# HR_C7000_DM32 register map
Vendor: Dahua Technology (chip); Baofeng (radio product); Series: HR_C7000; File version: 0.1-dm32re-draft
CPU: other r0p0, little endian, no MPU, no FPU, 0 interrupt priority bits
Registers are 32-bit, read-write, reset 0x0 unless marked. A register's access mark holds for its fields unless they carry their own. Offsets are from the block's base; [hi:lo] are bit positions.

## I2C0 — I2C0, Synopsys DesignWare APB I2C master/slave (DS §5.1, p.218-243). FW: no direct access or base literal found in program flash. QEMU docs record the ALPU-MP anti-clone handshake (I2C address 0x7a) on this controller; the IRAM code also contains a bit-banged GPIO I2C routine addressing 0x7a. Which path the stock firmware uses is not settled here.
Base 0x14060000
Same registers: I2C1 0x14070000, I2C2 0x14080000
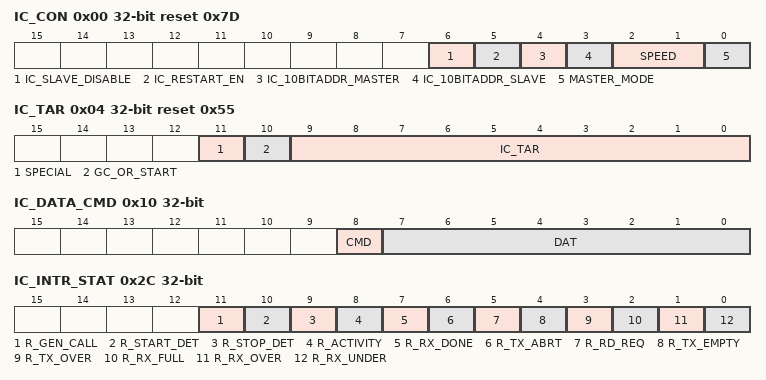
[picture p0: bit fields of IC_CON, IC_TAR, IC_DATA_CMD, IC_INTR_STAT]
0x00 IC_CON reset 0x7D — I2C Control registers. DS §5.1.6.1 p.226. Reset 0x7d (DS).
  [6] IC_SLAVE_DISABLE — I2C functions as a slave after reset. 0: slave enabled; 1: slave disabled [reset 0x1] [access RW]
  [5] IC_RESTART_EN — As master, whether RESTART is supported. 0: off; 1: enabled [reset 0x1] [access RW]
  [4] IC_10BITADDR_MASTER — As master, address mode. 0: 7-bit; 1: 10-bit [reset 0x1] [access RW]
  [3] IC_10BITADDR_SLAVE — As slave, address mode the I2C responds to. 0: 7-bit; 1: 10-bit [reset 0x1] [access RW]
  [2:1] SPEED — Speed mode. 1: standard (100 kbit/s); 2: fast (400 kbit/s); 3: high speed (3.4 Mbit/s, not supported) [reset 0x2] [access RW]
  [0] MASTER_MODE — Master enable. 0: master off; 1: master enabled [reset 0x1] [access RW]
0x04 IC_TAR reset 0x55 — I2C Destination Address Register. DS §5.1.6.2 p.228. Reset 0x55 (DS).
  [11] SPECIAL — Indicates whether the software executes a general call or start byte command. ( Not supported These two functions ) [reset 0x0] [access RW]
  [10] GC_OR_START — only when bit 11 is set to 1. It indicates whether the software is executing a general call or a start byte command. 0 : Broadcast call 1 : Start byte [reset 0x0] [access RW]
  [9:0] IC_TAR — Indicates the target slave address when I2C is used as the master . [reset 0x55] [access RW]
0x10 IC_DATA_CMD — I2C Send and receive data buffers and. DS §5.1.6.3 p.228. Reset 0x0 (DS).
  [8] CMD wo — I2C is used as a master , read and write control bits. 1 : Read 0 : Write [reset 0x0] [access WO]
  [7:0] DAT — Data sent to or received from the I2C bus . [reset 0x0] [access RW]
0x1C IC_FS_SCL_HCNT reset 0x5A — Fast SCL High level count. DS §5.1.6.4 p.228. Reset 0x5a (DS).
  [15:0] IC_FS_SCL_HCNT — Set in fast mode, SCL clock is active high when ic_clk Number of cycles [reset 0x5a] [access RW]
0x20 IC_FS_SCL_LCNT reset 0xA0 — Fast SCL Low level count. DS §5.1.6.5 p.228. Reset 0xa0 (DS).
  [15:0] IC_FS_SCL_LCNT — Set in fast mode, SCL clock is active low when ic_clk Number of cycles [reset 0xa0] [access RW]
0x2C IC_INTR_STAT ro — Interrupt Status. DS §5.1.6.6 p.230. Reset 0x0 (DS).
  [11] R_GEN_CALL — IC_RAW_INTR_STAT register for detailed explanation [reset 0x0] [access RO]
  [10] R_START_DET — R_START_DET [reset 0x0] [access RO]
  [9] R_STOP_DET — R_STOP_DET [reset 0x0] [access RO]
  [8] R_ACTIVITY — R_ACTIVITY [reset 0x0] [access RO]
  [7] R_RX_DONE — R_RX_DONE [reset 0x0] [access RO]
  [6] R_TX_ABRT — R_TX_ABRT [reset 0x0] [access RO]
  [5] R_RD_REQ — R_RD_REQ [reset 0x0] [access RO]
  [4] R_TX_EMPTY — R_TX_EMPTY [reset 0x0] [access RO]
  [3] R_TX_OVER — R_TX_OVER [reset 0x0] [access RO]
  [2] R_RX_FULL — R_RX_FULL [reset 0x0] [access RO]
  [1] R_RX_OVER — R_RX_OVER [reset 0x0] [access RO]
  [0] R_RX_UNDER — R_RX_UNDER [reset 0x0] [access RO]
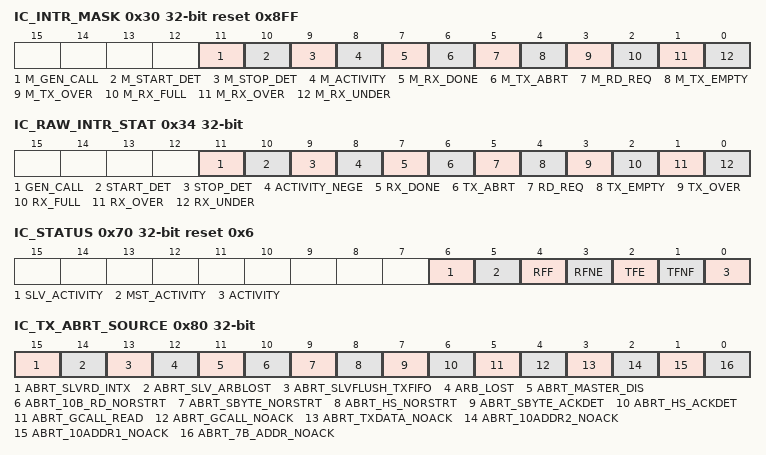
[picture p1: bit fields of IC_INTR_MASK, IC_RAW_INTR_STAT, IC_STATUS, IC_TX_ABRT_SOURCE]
0x30 IC_INTR_MASK reset 0x8FF — Interrupt mask. DS §5.1.6.7 p.230. Reset 0x8ff (DS).
  [11] M_GEN_CALL — IC_RAW_INTR_STAT register for detailed explanation [reset 0x1] [access RW]
  [10] M_START_DET — M_START_DET [reset 0x0] [access RW]
  [9] M_STOP_DET — M_STOP_DET [reset 0x0] [access RW]
  [8] M_ACTIVITY — M_ACTIVITY [reset 0x0] [access RW]
  [7] M_RX_DONE — M_RX_DONE [reset 0x1] [access RW]
  [6] M_TX_ABRT — M_TX_ABRT [reset 0x1] [access RW]
  [5] M_RD_REQ — M_RD_REQ [reset 0x1] [access RW]
  [4] M_TX_EMPTY — M_TX_EMPTY [reset 0x1] [access RW]
  [3] M_TX_OVER — M_TX_OVER [reset 0x1] [access RW]
  [2] M_RX_FULL — M_RX_FULL [reset 0x1] [access RW]
  [1] M_RX_OVER — M_RX_OVER [reset 0x1] [access RW]
  [0] M_RX_UNDER — M_RX_UNDER [reset 0x1] [access RW]
0x34 IC_RAW_INTR_STAT ro — Raw interrupt status. DS §5.1.6.8 p.230. Reset 0x0 (DS).
  [11] GEN_CALL — Valid when receiving a broadcast call address. (Not supported ) [reset 0x0] [access RO]
  [10] START_DET — master or slave mode, it indicates whether START or RESTART [reset 0x0] [access RO]
  [9] STOP_DET — master or slave mode, indicates whether STOP is detected [reset 0x0] [access RO]
  [8] ACTIVITY_NEGE — Indicates that I2C changes from active state to idle state. (i.e., I2C active state Falling edge ) [reset 0x0] [access RO]
  [7] RX_DONE — When I2C is used as a slave transmitter, if the master does not have an ACK sent byte, this position is 1 , indicating the end of transmission. [reset 0x0] [access RO]
  [6] TX_ABRT — I2C is used as a transmitter and the transmission is interrupted. See the cause for more information. IC_TX_ABRT_SOURCE Register [reset 0x0] [access RO]
  [5] RD_REQ — When I2C is used as a slave and other masters read data from I2C , this error will occur. When this interrupt is valid, I2C pulls SCL low and keeps it until the CPU responds to this interrupt and writes data to the IC_DATA_CMD register. [reset 0x0] [access RO]
  [4] TX_EMPTY — When the transmit FIFO data is lower than or equal to the threshold set in the IC_TX_TL register When the transmit FIFO threshold is exceeded, a transmit FIFO threshold interrupt will be generated. [reset 0x0] [access RO]
  [3] TX_OVER — When the transmit FIFO reaches the set depth and the processor continues to write data, Generates a transmit overflow interrupt. [reset 0x0] [access RO]
  [2] RX_FULL — When the receive FIFO data is greater than or equal to the threshold set by the IC_RX_TL register When the receive FIFO threshold value is reached, a receive FIFO threshold interrupt will be generated. [reset 0x0] [access RO]
  [1] RX_OVER — When the receive FIFO is full and continues to receive data, an overflow interrupt is generated. [reset 0x0] [access RO]
  [0] RX_UNDER — When the receive FIFO is empty and the processor reads data, an underflow interrupt is generated. [reset 0x0] [access RO]
0x38 IC_RX_TL reset 0x6 — Receive FIFO threshold. DS §5.1.6.9 p.232. Reset 0x6 (DS).
  [7:0] RX_TL — Set the receive FIFO threshold, ranging from 0 to 7. When the threshold is set to 7 , the receive FIFO data reaches 7 , which triggers the RX_FULL interrupt; when the threshold is set to 0-6 , RX_FULL interrupt will be triggered only when the value is greater than this threshold . [reset 0x6] [access RW]
0x3C IC_TX_TL reset 0x6 — Transmit FIFO threshold. DS §5.1.6.10 p.233. Reset 0x6 (DS).
  [7:0] TX_TL — Set the threshold of the transmit FIFO , ranging from 0 to 7. If the threshold is less than or equal to the threshold, the Send TX_EMPTY interrupt. [reset 0x6] [access RW]
0x40 IC_CLR_INTR ro — Clear Interrupt. DS §5.1.6.11 p.233. Reset 0x0 (DS).
  [0] CLR_INTR — Reading this register clears combined interrupts, all single interrupts, and IC_TX_ABRT_SOURCE Register. Only software- clearable interrupts can be cleared . [reset 0x0] [access RO]
0x44 IC_CLR_RX_UNDER ro — Clear interrupt RX_UNDER. DS §5.1.6.12 p.234. Reset 0x0 (DS).
  [0] CLR_RX_UNDER — Clear the RX_UNDER interrupt. [reset 0x0] [access RO]
0x48 IC_CLR_RX_OVER ro — Clear interrupt RX_OVER. DS §5.1.6.13 p.234. Reset 0x0 (DS).
  [0] CLR_RX_OVER — Clear the RX_OVER interrupt. [reset 0x0] [access RO]
0x4C IC_CLR_TX_OVER ro — Clear interrupt TX_OVER. DS §5.1.6.14 p.234. Reset 0x0 (DS).
  [0] CLR_TX_OVER — Clears the TX_OVER interrupt. [reset 0x0] [access RO]
0x50 IC_CLR_RD_REQ ro — Clear interrupt RD_REQ. DS §5.1.6.15 p.234. Reset 0x0 (DS).
  [0] CLR_RD_REQ — Clear RD_REQ Interrupt. [reset 0x0] [access RO]
0x54 IC_CLR_TX_ABRT ro — Clear interrupt TX_ABRT. DS §5.1.6.16 p.234. Reset 0x0 (DS).
  [0] CLR_TX_ABRT — Reading the register can clear the TX_ABRT interrupt and IC_TX_ABRT_SOURCE register. [reset 0x0] [access RO]
0x58 IC_CLR_RX_DONE ro — Clear interrupt RX_DONE. DS §5.1.6.17 p.236. Reset 0x0 (DS).
  [0] CLR_RX_DONE — Clear RX_DONE Interrupt. [reset 0x0] [access RO]
0x5C IC_CLR_ACTIVITY ro — Clear interrupt activity. DS §5.1.6.18 p.236. Reset 0x0 (DS).
  [0] CLR_ACTIVITY — Clear ACTIVITY Interrupt. [reset 0x0] [access RO]
0x60 IC_CLR_STOP_DET ro — Clear interrupt STOP_DET. DS §5.1.6.19 p.236. Reset 0x0 (DS).
  [0] CLR_STOP_DET — Clear STOP_DET Interrupt. [reset 0x0] [access RO]
0x64 IC_CLR_START_DET ro — Clear interrupt START_DET. DS §5.1.6.20 p.236. Reset 0x0 (DS).
  [0] CLR_START_DET — Clear START_DET Interrupt. [reset 0x0] [access RO]
0x6C IC_ENABLE — I2C Enable register. DS §5.1.6.21 p.236. Reset 0x0 (DS).
  [0] ENABLE — Controls I2C enable. 0 : I2C off 1 : I2C enabled [reset 0x0] [access RW]
0x70 IC_STATUS ro reset 0x6 — I2C Status Register. DS §5.1.6.22 p.238. Reset 0x6 (DS).
  [6] SLV_ACTIVITY — The slave state machine is active. 0 : The slave state machine is in idle state 1 : The slave state machine is not in idle state [reset 0x0] [access RO]
  [5] MST_ACTIVITY — The master state machine is active. 0 : The master state machine is in idle state 1 : The master state machine is not in idle state [reset 0x0] [access RO]
  [4] RFF — The receive FIFO is completely full. 0 : Receive FIFO is not full 1 : Receive FIFO full [reset 0x0] [access RO]
  [3] RFNE — The receive FIFO is not empty. 0 : Receive FIFO empty 1 : Receive FIFO is not empty [reset 0x0] [access RO]
  [2] TFE — The transmit FIFO is completely empty. 0 : Transmit FIFO is not empty 1 : Transmit FIFO empty [reset 0x1] [access RO]
  [1] TFNF — The transmit FIFO is not full. 0 : Transmit FIFO full 1 : Transmit FIFO is not full [reset 0x1] [access RO]
  [0] ACTIVITY — I2C is active [reset 0x0] [access RO]
0x74 IC_TXFLR ro — Transmit FIFO water level register. DS §5.1.6.23 p.238. Reset 0x0 (DS).
  [3:0] TXFLR — Number of valid data in the transmit FIFO [reset 0x0] [access RO]
0x78 IC_RXFLR ro — Receive FIFO water level register. DS §5.1.6.24 p.238. Reset 0x0 (DS).
  [3:0] RXFLR — Number of valid data in receive FIFO [reset 0x0] [access RO]
0x80 IC_TX_ABRT_SOURCE ro — I2C Transfer end status register. DS §5.1.6.25 p.240. Reset 0x0 (DS).
  [15] ABRT_SLVRD_INTX — When I2C is used as a slave-transmitter , I2C requests to send data, and the processor Write and read commands to the transmit FIFO . [reset 0x0] [access RO]
  [14] ABRT_SLV_ARBLOST — As a Slave-Transmitter , when transmitting data to the master , the loss of cut. [reset 0x0] [access RO]
  [13] ABRT_SLVFLUSH_TXFIFO — As a Slave-Transmitter , I2C receives a read command and sends the data in the FIFO. There is already some data, and a TX_ABRT interrupt will be initiated to release the original data [reset 0x0] [access RO]
  [12] ARB_LOST — acting as a Master-Transmitter or Slave-Transmitter , the cut [reset 0x0] [access RO]
  [11] ABRT_MASTER_DIS — acting as a master , access the master when the master mode is shut down . [reset 0x0] [access RO]
  [10] ABRT_10B_RD_NORSTRT — As Master-Receiver , the RESTART function is turned off, but in the 10- bit Sending a read command in address mode [reset 0x0] [access RO]
  [9] ABRT_SBYTE_NORSTRT — As a master , RESTART is turned off, and the start byte is sent [reset 0x0] [access RO]
  [8] ABRT_HS_NORSTRT — As a master , the RESTART function is turned off, but an attempt is made to operate in high-speed mode Transfer data [reset 0x0] [access RO]
  [7] ABRT_SBYTE_ACKDET — As a master , I2C sends the start byte, and the start byte is acked ( positive Normally, the start byte does not need ack ) [reset 0x0] [access RO]
  [6] ABRT_HS_ACKDET — acting as a master , when I2C is in high-speed mode, the high-speed master code is acked . ack is required under normal circumstances ) [reset 0x0] [access RO]
  [5] ABRT_GCALL_READ — As a master-tansmitter , I2C issues a general call when reading data [reset 0x0] [access RO]
  [4] ABRT_GCALL_NOACK — As a master-tansmitter , the broadcast call address issued has no slave response. [reset 0x0] [access RO]
  [3] ABRT_TXDATA_NOACK — acting as a master-tansmitter , the address sent gets ack , but then The data sent out does not receive ack from the slave [reset 0x0] [access RO]
  [2] ABRT_10ADDR2_NOACK — As a master , the address mode is 10-bit mode, and the second address issued is No response was received from any slave . [reset 0x0] [access RO]
  [1] ABRT_10ADDR1_NOACK — I2C is used as a master , the address mode is 10-bit mode, and the first The address did not receive any slave response. [reset 0x0] [access RO]
  [0] ABRT_7B_ADDR_NOACK — I2C is used as a master , the address mode is 7-bit mode, and the address sent is not response was received from any slave . [reset 0x0] [access RO]
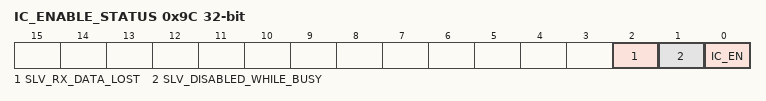
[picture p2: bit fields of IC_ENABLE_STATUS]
0x9C IC_ENABLE_STATUS ro — I2C Enable Status Register. DS §5.1.6.26 p.242. Reset 0x0 (DS).
  [2] SLV_RX_DATA_LOST — only when bit0 is 0 , indicating that in slave- reveive mode, after receiving >= 1 byte of data, the I2C enable is turned off and the data transmission is abandoned. When it is set to 1 , it means that the transmission has entered the data stage and after receiving at least 1 byte of data, the I2C enable is turned off. Regardless of whether ack is received , the transmission is abandoned. When it is set to 0 , it means that when I2C is turned off, The data transmission phase has not yet begun. ( I2C is not supported as a slave .) [reset 0x0] [access RO]
  [1] SLV_DISABLED_WHILE_BUSY — This bit is valid only when bit0 is 0. It indicates that when I2C is used as a slave , the data transmission is terminated because the I2C enable is turned off. When I2C is receiving the address byte or Slave-Receiver mode, when I2C is receiving address and data bytes, the CPU writes 0 to the IC_ENABLE register , which will cause this position to be set to 1. (Not supported) I2C as slave ) [reset 0x0] [access RO]
  [0] IC_EN — Indicates whether I2C is enabled. 0 : I2C is inactive 1 : I2C enabled [reset 0x0] [access RO]
0xA0 IC_START — Control data starts sending. DS §5.1.6.27 p.242. Reset 0x0 (DS).
  [0] START — Controls the I2C to start sending data. This register must be configured after the IC_ENABLE register is enabled. When there is data in the FIFO , writing 1 to this register will start sending data. 0 : Do not start 1 : Start [reset 0x0] [access RW]
